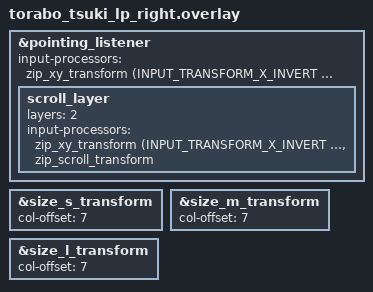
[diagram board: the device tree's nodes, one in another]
#include "torabo_tsuki_lp.dtsi"
#include <input/processors.dtsi>
#include <dt-bindings/zmk/input_transform.h>

&pointing_listener {
    input-processors = <&zip_xy_transform (INPUT_TRANSFORM_X_INVERT | INPUT_TRANSFORM_Y_INVERT)>;

    // レイヤー2が押された時だけ発動する「上書きルール」
    scroll_layer {
        layers = <2>;
        input-processors = 
            <&zip_xy_transform (INPUT_TRANSFORM_X_INVERT | INPUT_TRANSFORM_Y_INVERT)>,
            <&zip_scroll_transform>;
    };
};

&size_s_transform {
    col-offset = <7>;
};

&size_m_transform {
    col-offset = <7>;
};

&size_l_transform {
    col-offset = <7>;
};
